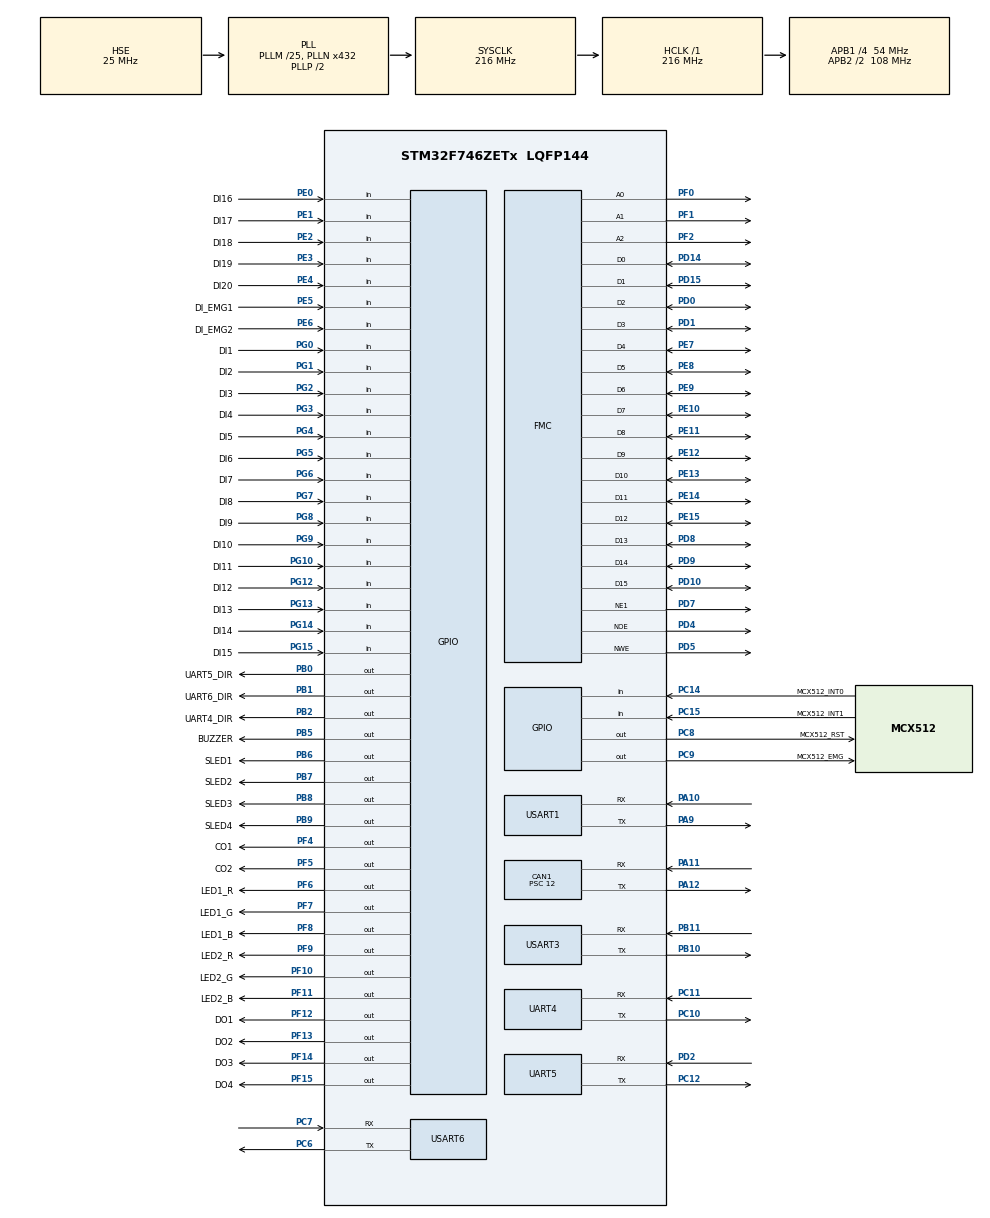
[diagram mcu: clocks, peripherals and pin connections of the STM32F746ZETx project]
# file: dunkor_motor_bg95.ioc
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CAN1.BS1=CAN_BS1_15TQ
CAN1.BS2=CAN_BS2_2TQ
CAN1.CalculateBaudRate=250000
CAN1.CalculateTimeBit=4000
CAN1.CalculateTimeQuantum=222.22222222222223
CAN1.Prescaler=12
CORTEX_M7.AccessPermission-Cortex_Memory_Protection_Unit_Region1_Settings=MPU_REGION_FULL_ACCESS
CORTEX_M7.AccessPermission-Cortex_Memory_Protection_Unit_Region2_Settings=MPU_REGION_FULL_ACCESS
CORTEX_M7.BaseAddress-Cortex_Memory_Protection_Unit_Region0_Settings=0x90000000
CORTEX_M7.CPU_DCache=Enabled
CORTEX_M7.CPU_ICache=Enabled
CORTEX_M7.DisableExec-Cortex_Memory_Protection_Unit_Region0_Settings=MPU_INSTRUCTION_ACCESS_DISABLE
CORTEX_M7.DisableExec-Cortex_Memory_Protection_Unit_Region1_Settings=MPU_INSTRUCTION_ACCESS_DISABLE
CORTEX_M7.Enable-Cortex_Memory_Protection_Unit_Region0_Settings=MPU_REGION_ENABLE
CORTEX_M7.Enable-Cortex_Memory_Protection_Unit_Region1_Settings=MPU_REGION_ENABLE
CORTEX_M7.Enable-Cortex_Memory_Protection_Unit_Region2_Settings=MPU_REGION_ENABLE
CORTEX_M7.IsBufferable-Cortex_Memory_Protection_Unit_Region1_Settings=MPU_ACCESS_BUFFERABLE
CORTEX_M7.IsBufferable-Cortex_Memory_Protection_Unit_Region2_Settings=MPU_ACCESS_BUFFERABLE
CORTEX_M7.IsCacheable-Cortex_Memory_Protection_Unit_Region1_Settings=MPU_ACCESS_CACHEABLE
CORTEX_M7.IsCacheable-Cortex_Memory_Protection_Unit_Region2_Settings=MPU_ACCESS_CACHEABLE
CORTEX_M7.MPU_Control=__NULL
CORTEX_M7.PREFETCH_ENABLE=0
CORTEX_M7.Size-Cortex_Memory_Protection_Unit_Region0_Settings=MPU_REGION_SIZE_512MB
CORTEX_M7.Size-Cortex_Memory_Protection_Unit_Region1_Settings=MPU_REGION_SIZE_16MB
CORTEX_M7.Size-Cortex_Memory_Protection_Unit_Region2_Settings=MPU_REGION_SIZE_1MB
FMC.AddressSetupTime1=5
FMC.BusTurnAroundDuration1=4
FMC.DataSetupTime1=4
FMC.WriteFifo1=FMC_WRITE_FIFO_DISABLE
FMC.WriteFifo2=FMC_WRITE_FIFO_DISABLE
FMC.WriteFifo3=FMC_WRITE_FIFO_DISABLE
FMC.WriteFifo4=FMC_WRITE_FIFO_DISABLE
Mcu.Family=STM32F7
Mcu.Name=STM32F746ZETx
Mcu.Package=LQFP144
NVIC.CAN1_RX0_IRQn=true\:8\:0\:true\:false\:true\:true\:true\:true
NVIC.PriorityGroup=NVIC_PRIORITYGROUP_4
NVIC.TIM6_DAC_IRQn=true\:15\:0\:false\:false\:true\:false\:true\:true
NVIC.TIM7_IRQn=true\:7\:0\:true\:false\:true\:true\:true\:true
NVIC.TimeBase=TIM6_DAC_IRQn
NVIC.TimeBaseIP=TIM6
NVIC.UART4_IRQn=true\:8\:0\:true\:false\:true\:true\:true\:true
NVIC.UART5_IRQn=true\:0\:0\:false\:false\:true\:true\:true\:true
NVIC.USART1_IRQn=true\:14\:0\:true\:false\:true\:true\:true\:true
NVIC.USART3_IRQn=true\:8\:0\:true\:false\:true\:true\:true\:true
NVIC.USART6_IRQn=true\:8\:0\:true\:false\:true\:true\:true\:true
PA10.Mode=Asynchronous
PA10.Signal=USART1_RX
PA11.Mode=CAN_Activate
PA11.Signal=CAN1_RX
PA12.Mode=CAN_Activate
PA12.Signal=CAN1_TX
PA13.Mode=JTAG_5_pins
PA13.Signal=SYS_JTMS-SWDIO
PA14.Mode=JTAG_5_pins
PA14.Signal=SYS_JTCK-SWCLK
PA15.Mode=JTAG_5_pins
PA15.Signal=SYS_JTDI
PA9.Mode=Asynchronous
PA9.Signal=USART1_TX
PB0.GPIO_Label=UART5_DIR
PB0.Signal=GPIO_Output
PB1.GPIO_Label=UART6_DIR
PB1.Signal=GPIO_Output
PB10.Mode=Asynchronous
PB10.Signal=USART3_TX
PB11.Mode=Asynchronous
PB11.Signal=USART3_RX
PB2.GPIO_Label=UART4_DIR
PB2.Signal=GPIO_Output
PB3.Mode=JTAG_5_pins
PB3.Signal=SYS_JTDO-SWO
PB4.Mode=JTAG_5_pins
PB4.Signal=SYS_JTRST
PB5.GPIO_Label=BUZZER
PB5.GPIO_Speed=GPIO_SPEED_FREQ_HIGH
PB5.Signal=GPIO_Output
PB6.GPIO_Label=SLED1
PB6.Signal=GPIO_Output
PB7.GPIO_Label=SLED2
PB7.Signal=GPIO_Output
PB8.GPIO_Label=SLED3
PB8.Signal=GPIO_Output
PB9.GPIO_Label=SLED4
PB9.Signal=GPIO_Output
PC10.Mode=Asynchronous
PC10.Signal=UART4_TX
PC11.Mode=Asynchronous
PC11.Signal=UART4_RX
PC12.Mode=Asynchronous
PC12.Signal=UART5_TX
PC14/OSC32_IN.GPIO_Label=MCX512_INT0
PC14/OSC32_IN.Signal=GPIO_Input
PC15/OSC32_OUT.GPIO_Label=MCX512_INT1
PC15/OSC32_OUT.Signal=GPIO_Input
PC6.Mode=Asynchronous
PC6.Signal=USART6_TX
PC7.Mode=Asynchronous
PC7.Signal=USART6_RX
PC8.GPIO_Label=MCX512_RST
PC8.Signal=GPIO_Output
PC9.GPIO_Label=MCX512_EMG
PC9.Signal=GPIO_Output
PD0.Signal=FMC_D2_DA2
PD1.Signal=FMC_D3_DA3
PD10.Signal=FMC_D15_DA15
PD14.Signal=FMC_D0_DA0
PD15.Signal=FMC_D1_DA1
PD2.Mode=Asynchronous
PD2.Signal=UART5_RX
PD4.Signal=FMC_NOE
PD5.Signal=FMC_NWE
PD7.Mode=NorPsramChipSelect1_1
PD7.Signal=FMC_NE1
PD8.Signal=FMC_D13_DA13
PD9.Signal=FMC_D14_DA14
PE0.GPIO_Label=DI16
PE0.Signal=GPIO_Input
PE1.GPIO_Label=DI17
PE1.Signal=GPIO_Input
PE10.Signal=FMC_D7_DA7
PE11.Signal=FMC_D8_DA8
PE12.Signal=FMC_D9_DA9
PE13.Signal=FMC_D10_DA10
PE14.Signal=FMC_D11_DA11
PE15.Signal=FMC_D12_DA12
PE2.GPIO_Label=DI18
PE2.Signal=GPIO_Input
PE3.GPIO_Label=DI19
PE3.Signal=GPIO_Input
PE4.GPIO_Label=DI20
PE4.Signal=GPIO_Input
PE5.GPIO_Label=DI_EMG1
PE5.Signal=GPIO_Input
PE6.GPIO_Label=DI_EMG2
PE6.Signal=GPIO_Input
PE7.Signal=FMC_D4_DA4
PE8.Signal=FMC_D5_DA5
PE9.Signal=FMC_D6_DA6
PF0.Signal=FMC_A0
PF1.Signal=FMC_A1
PF10.GPIO_Label=LED2_G
PF10.Signal=GPIO_Output
PF11.GPIO_Label=LED2_B
PF11.Signal=GPIO_Output
PF12.GPIO_Label=DO1
PF12.Signal=GPIO_Output
PF13.GPIO_Label=DO2
PF13.Signal=GPIO_Output
PF14.GPIO_Label=DO3
PF14.Signal=GPIO_Output
PF15.GPIO_Label=DO4
PF15.Signal=GPIO_Output
PF2.Signal=FMC_A2
PF4.GPIO_Label=CO1
PF4.Signal=GPIO_Output
PF5.GPIO_Label=CO2
PF5.Signal=GPIO_Output
PF6.GPIO_Label=LED1_R
PF6.Signal=GPIO_Output
PF7.GPIO_Label=LED1_G
PF7.Signal=GPIO_Output
PF8.GPIO_Label=LED1_B
PF8.Signal=GPIO_Output
PF9.GPIO_Label=LED2_R
PF9.Signal=GPIO_Output
PG0.GPIO_Label=DI1
PG0.Signal=GPIO_Input
PG1.GPIO_Label=DI2
PG1.Signal=GPIO_Input
PG10.GPIO_Label=DI11
PG10.Signal=GPIO_Input
PG12.GPIO_Label=DI12
PG12.Signal=GPIO_Input
PG13.GPIO_Label=DI13
PG13.Signal=GPIO_Input
PG14.GPIO_Label=DI14
PG14.Signal=GPIO_Input
PG15.GPIO_Label=DI15
PG15.Signal=GPIO_Input
PG2.GPIO_Label=DI3
PG2.Signal=GPIO_Input
PG3.GPIO_Label=DI4
PG3.Signal=GPIO_Input
PG4.GPIO_Label=DI5
PG4.Signal=GPIO_Input
PG5.GPIO_Label=DI6
PG5.Signal=GPIO_Input
PG6.GPIO_Label=DI7
PG6.Signal=GPIO_Input
PG7.GPIO_Label=DI8
PG7.Signal=GPIO_Input
PG8.GPIO_Label=DI9
PG8.Signal=GPIO_Input
PG9.GPIO_Label=DI10
PG9.Signal=GPIO_Input
PH0/OSC_IN.Mode=HSE-External-Oscillator
PH0/OSC_IN.Signal=RCC_OSC_IN
PH1/OSC_OUT.Mode=HSE-External-Oscillator
PH1/OSC_OUT.Signal=RCC_OSC_OUT
ProjectManager.HeapSize=0x2000
ProjectManager.StackSize=0x4000
ProjectManager.TargetToolchain=STM32CubeIDE
RCC.AHBFreq_Value=216000000
RCC.APB1CLKDivider=RCC_HCLK_DIV4
RCC.APB1Freq_Value=54000000
RCC.APB1TimFreq_Value=108000000
RCC.APB2CLKDivider=RCC_HCLK_DIV2
RCC.APB2Freq_Value=108000000
RCC.APB2TimFreq_Value=216000000
RCC.CortexFreq_Value=216000000
RCC.HCLKFreq_Value=216000000
RCC.HSE_VALUE=25000000
RCC.HSI_VALUE=16000000
RCC.LSE_VALUE=32768
RCC.PLLM=25
RCC.PLLN=432
RCC.PLLSourceVirtual=RCC_PLLSOURCE_HSE
RCC.SYSCLKFreq_VALUE=216000000
RCC.SYSCLKSource=RCC_SYSCLKSOURCE_PLLCLK
RCC.USBFreq_Value=216000000
RCC.VCOOutputFreq_Value=432000000
SH.FMC_A0.0=FMC_A0,3b-a1
SH.FMC_A1.0=FMC_A1,3b-a1
SH.FMC_A2.0=FMC_A2,3b-a1
SH.FMC_D0_DA0.0=FMC_D0,16b-d1
SH.FMC_D10_DA10.0=FMC_D10,16b-d1
SH.FMC_D11_DA11.0=FMC_D11,16b-d1
SH.FMC_D12_DA12.0=FMC_D12,16b-d1
SH.FMC_D13_DA13.0=FMC_D13,16b-d1
SH.FMC_D14_DA14.0=FMC_D14,16b-d1
SH.FMC_D15_DA15.0=FMC_D15,16b-d1
SH.FMC_D1_DA1.0=FMC_D1,16b-d1
SH.FMC_D2_DA2.0=FMC_D2,16b-d1
SH.FMC_D3_DA3.0=FMC_D3,16b-d1
SH.FMC_D4_DA4.0=FMC_D4,16b-d1
SH.FMC_D5_DA5.0=FMC_D5,16b-d1
SH.FMC_D6_DA6.0=FMC_D6,16b-d1
SH.FMC_D7_DA7.0=FMC_D7,16b-d1
SH.FMC_D8_DA8.0=FMC_D8,16b-d1
SH.FMC_D9_DA9.0=FMC_D9,16b-d1
SH.FMC_NOE.0=FMC_NOE,Psram1
SH.FMC_NWE.0=FMC_NWE,Psram1
TIM7.AutoReloadPreload=TIM_AUTORELOAD_PRELOAD_ENABLE
TIM7.Period=99
TIM7.Prescaler=107
UART5.Parity=PARITY_EVEN
UART5.WordLength=WORDLENGTH_9B
USART1.VirtualMode-Asynchronous=VM_ASYNC
USART3.VirtualMode-Asynchronous=VM_ASYNC
USART6.Parity=PARITY_EVEN
USART6.VirtualMode-Asynchronous=VM_ASYNC
USART6.WordLength=WORDLENGTH_9B
VP_SYS_VS_tim6.Mode=TIM6
VP_TIM7_VS_ClockSourceINT.Mode=Enable_Timer
board=custom

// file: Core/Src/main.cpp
/* USER CODE BEGIN Header */
/**
  ******************************************************************************
  * @file           : main.c
  * @brief          : Main program body
  ******************************************************************************
  * @attention
  *
  * Copyright (c) 2023 STMicroelectronics.
  * All rights reserved.
  *
  * This software is licensed under terms that can be found in the LICENSE file
  * in the root directory of this software component.
  * If no LICENSE file comes with this software, it is provided AS-IS.
  *
  ******************************************************************************
  */
/* USER CODE END Header */
#include "main.h"

/* USER CODE BEGIN Includes */
#include "lift_motor/bg95.h"
/* USER CODE END Includes */

CAN_HandleTypeDef hcan1;

TIM_HandleTypeDef htim7;

UART_HandleTypeDef huart4;
UART_HandleTypeDef huart5;
UART_HandleTypeDef huart1;
UART_HandleTypeDef huart3;
UART_HandleTypeDef huart6;

SRAM_HandleTypeDef hsram1;

void SystemClock_Config(void);
static void MX_GPIO_Init(void);
static void MX_CAN1_Init(void);
static void MX_FMC_Init(void);
static void MX_UART4_Init(void);
static void MX_USART1_UART_Init(void);
static void MX_USART3_UART_Init(void);
static void MX_USART6_UART_Init(void);
static void MX_UART5_Init(void);
static void MX_TIM7_Init(void);

int main(void)
{

  /* Enable I-Cache---------------------------------------------------------*/
  SCB_EnableICache();

  /* Enable D-Cache---------------------------------------------------------*/
  SCB_EnableDCache();

  /* MCU Configuration--------------------------------------------------------*/

  /* Reset of all peripherals, Initializes the Flash interface and the Systick. */
  HAL_Init();

  /* Configure the system clock */
  SystemClock_Config();

  /* Initialize all configured peripherals */
  MX_GPIO_Init();
  MX_CAN1_Init();
  MX_FMC_Init();
  MX_UART4_Init();
  MX_USART1_UART_Init();
  MX_USART3_UART_Init();
  MX_USART6_UART_Init();
  MX_UART5_Init();
  MX_TIM7_Init();

  /* USER CODE BEGIN 2 */
  /*Constructor*/
  BG95 lift_motor(&hcan1, 127);

  lift_motor.Initialization();
  /* USER CODE END 2 */

  /* Infinite loop */
  while (1)
  {
	  //lift_motor.VelCommand(300, 100, 100);

	  lift_motor.Drive();

	  HAL_Delay(1);

	  //int32_t your_pos_val = lift_motor.GetMotorPosition();

  }
}

void SystemClock_Config(void)
{
  RCC_OscInitTypeDef RCC_OscInitStruct = {0};
  RCC_ClkInitTypeDef RCC_ClkInitStruct = {0};

  /** Configure the main internal regulator output voltage
  */
  __HAL_RCC_PWR_CLK_ENABLE();
  __HAL_PWR_VOLTAGESCALING_CONFIG(PWR_REGULATOR_VOLTAGE_SCALE1);

  /** Initializes the RCC Oscillators according to the specified parameters
  * in the RCC_OscInitTypeDef structure.
  */
  RCC_OscInitStruct.OscillatorType = RCC_OSCILLATORTYPE_HSE;
  RCC_OscInitStruct.HSEState = RCC_HSE_ON;
  RCC_OscInitStruct.PLL.PLLState = RCC_PLL_ON;
  RCC_OscInitStruct.PLL.PLLSource = RCC_PLLSOURCE_HSE;
  RCC_OscInitStruct.PLL.PLLM = 25;
  RCC_OscInitStruct.PLL.PLLN = 432;
  RCC_OscInitStruct.PLL.PLLP = RCC_PLLP_DIV2;
  RCC_OscInitStruct.PLL.PLLQ = 2;
  if (HAL_RCC_OscConfig(&RCC_OscInitStruct) != HAL_OK)
  {
    Error_Handler();
  }

  /** Activate the Over-Drive mode
  */
  if (HAL_PWREx_EnableOverDrive() != HAL_OK)
  {
    Error_Handler();
  }

  /** Initializes the CPU, AHB and APB buses clocks
  */
  RCC_ClkInitStruct.ClockType = RCC_CLOCKTYPE_HCLK|RCC_CLOCKTYPE_SYSCLK
                              |RCC_CLOCKTYPE_PCLK1|RCC_CLOCKTYPE_PCLK2;
  RCC_ClkInitStruct.SYSCLKSource = RCC_SYSCLKSOURCE_PLLCLK;
  RCC_ClkInitStruct.AHBCLKDivider = RCC_SYSCLK_DIV1;
  RCC_ClkInitStruct.APB1CLKDivider = RCC_HCLK_DIV4;
  RCC_ClkInitStruct.APB2CLKDivider = RCC_HCLK_DIV2;

  if (HAL_RCC_ClockConfig(&RCC_ClkInitStruct, FLASH_LATENCY_7) != HAL_OK)
  {
    Error_Handler();
  }
}

static void MX_CAN1_Init(void)
{

  hcan1.Instance = CAN1;
  hcan1.Init.Prescaler = 12;
  hcan1.Init.Mode = CAN_MODE_NORMAL;
  hcan1.Init.SyncJumpWidth = CAN_SJW_1TQ;
  hcan1.Init.TimeSeg1 = CAN_BS1_15TQ;
  hcan1.Init.TimeSeg2 = CAN_BS2_2TQ;
  hcan1.Init.TimeTriggeredMode = DISABLE;
  hcan1.Init.AutoBusOff = DISABLE;
  hcan1.Init.AutoWakeUp = DISABLE;
  hcan1.Init.AutoRetransmission = DISABLE;
  hcan1.Init.ReceiveFifoLocked = DISABLE;
  hcan1.Init.TransmitFifoPriority = DISABLE;
  if (HAL_CAN_Init(&hcan1) != HAL_OK)
  {
    Error_Handler();
  }

}

static void MX_TIM7_Init(void)
{

  TIM_MasterConfigTypeDef sMasterConfig = {0};

  htim7.Instance = TIM7;
  htim7.Init.Prescaler = 107;
  htim7.Init.CounterMode = TIM_COUNTERMODE_UP;
  htim7.Init.Period = 99;
  htim7.Init.AutoReloadPreload = TIM_AUTORELOAD_PRELOAD_ENABLE;
  if (HAL_TIM_Base_Init(&htim7) != HAL_OK)
  {
    Error_Handler();
  }
  sMasterConfig.MasterOutputTrigger = TIM_TRGO_RESET;
  sMasterConfig.MasterSlaveMode = TIM_MASTERSLAVEMODE_DISABLE;
  if (HAL_TIMEx_MasterConfigSynchronization(&htim7, &sMasterConfig) != HAL_OK)
  {
    Error_Handler();
  }

}

static void MX_UART4_Init(void)
{

  huart4.Instance = UART4;
  huart4.Init.BaudRate = 115200;
  huart4.Init.WordLength = UART_WORDLENGTH_8B;
  huart4.Init.StopBits = UART_STOPBITS_1;
  huart4.Init.Parity = UART_PARITY_NONE;
  huart4.Init.Mode = UART_MODE_TX_RX;
  huart4.Init.HwFlowCtl = UART_HWCONTROL_NONE;
  huart4.Init.OverSampling = UART_OVERSAMPLING_16;
  huart4.Init.OneBitSampling = UART_ONE_BIT_SAMPLE_DISABLE;
  huart4.AdvancedInit.AdvFeatureInit = UART_ADVFEATURE_NO_INIT;
  if (HAL_UART_Init(&huart4) != HAL_OK)
  {
    Error_Handler();
  }

}

static void MX_UART5_Init(void)
{

  huart5.Instance = UART5;
  huart5.Init.BaudRate = 115200;
  huart5.Init.WordLength = UART_WORDLENGTH_9B;
  huart5.Init.StopBits = UART_STOPBITS_1;
  huart5.Init.Parity = UART_PARITY_EVEN;
  huart5.Init.Mode = UART_MODE_TX_RX;
  huart5.Init.HwFlowCtl = UART_HWCONTROL_NONE;
  huart5.Init.OverSampling = UART_OVERSAMPLING_16;
  huart5.Init.OneBitSampling = UART_ONE_BIT_SAMPLE_DISABLE;
  huart5.AdvancedInit.AdvFeatureInit = UART_ADVFEATURE_NO_INIT;
  if (HAL_UART_Init(&huart5) != HAL_OK)
  {
    Error_Handler();
  }

}

static void MX_USART1_UART_Init(void)
{

  huart1.Instance = USART1;
  huart1.Init.BaudRate = 115200;
  huart1.Init.WordLength = UART_WORDLENGTH_8B;
  huart1.Init.StopBits = UART_STOPBITS_1;
  huart1.Init.Parity = UART_PARITY_NONE;
  huart1.Init.Mode = UART_MODE_TX_RX;
  huart1.Init.HwFlowCtl = UART_HWCONTROL_NONE;
  huart1.Init.OverSampling = UART_OVERSAMPLING_16;
  huart1.Init.OneBitSampling = UART_ONE_BIT_SAMPLE_DISABLE;
  huart1.AdvancedInit.AdvFeatureInit = UART_ADVFEATURE_NO_INIT;
  if (HAL_UART_Init(&huart1) != HAL_OK)
  {
    Error_Handler();
  }

}

static void MX_USART3_UART_Init(void)
{

  huart3.Instance = USART3;
  huart3.Init.BaudRate = 115200;
  huart3.Init.WordLength = UART_WORDLENGTH_8B;
  huart3.Init.StopBits = UART_STOPBITS_1;
  huart3.Init.Parity = UART_PARITY_NONE;
  huart3.Init.Mode = UART_MODE_TX_RX;
  huart3.Init.HwFlowCtl = UART_HWCONTROL_NONE;
  huart3.Init.OverSampling = UART_OVERSAMPLING_16;
  huart3.Init.OneBitSampling = UART_ONE_BIT_SAMPLE_DISABLE;
  huart3.AdvancedInit.AdvFeatureInit = UART_ADVFEATURE_NO_INIT;
  if (HAL_UART_Init(&huart3) != HAL_OK)
  {
    Error_Handler();
  }

}

static void MX_USART6_UART_Init(void)
{

  huart6.Instance = USART6;
  huart6.Init.BaudRate = 115200;
  huart6.Init.WordLength = UART_WORDLENGTH_9B;
  huart6.Init.StopBits = UART_STOPBITS_1;
  huart6.Init.Parity = UART_PARITY_EVEN;
  huart6.Init.Mode = UART_MODE_TX_RX;
  huart6.Init.HwFlowCtl = UART_HWCONTROL_NONE;
  huart6.Init.OverSampling = UART_OVERSAMPLING_16;
  huart6.Init.OneBitSampling = UART_ONE_BIT_SAMPLE_DISABLE;
  huart6.AdvancedInit.AdvFeatureInit = UART_ADVFEATURE_NO_INIT;
  if (HAL_UART_Init(&huart6) != HAL_OK)
  {
    Error_Handler();
  }

}

/* FMC initialization function */
static void MX_FMC_Init(void)
{

  FMC_NORSRAM_TimingTypeDef Timing = {0};

  /** Perform the SRAM1 memory initialization sequence
  */
  hsram1.Instance = FMC_NORSRAM_DEVICE;
  hsram1.Extended = FMC_NORSRAM_EXTENDED_DEVICE;
  /* hsram1.Init */
  hsram1.Init.NSBank = FMC_NORSRAM_BANK1;
  hsram1.Init.DataAddressMux = FMC_DATA_ADDRESS_MUX_DISABLE;
  hsram1.Init.MemoryType = FMC_MEMORY_TYPE_PSRAM;
  hsram1.Init.MemoryDataWidth = FMC_NORSRAM_MEM_BUS_WIDTH_16;
  hsram1.Init.BurstAccessMode = FMC_BURST_ACCESS_MODE_DISABLE;
  hsram1.Init.WaitSignalPolarity = FMC_WAIT_SIGNAL_POLARITY_LOW;
  hsram1.Init.WaitSignalActive = FMC_WAIT_TIMING_BEFORE_WS;
  hsram1.Init.WriteOperation = FMC_WRITE_OPERATION_DISABLE;
  hsram1.Init.WaitSignal = FMC_WAIT_SIGNAL_DISABLE;
  hsram1.Init.ExtendedMode = FMC_EXTENDED_MODE_DISABLE;
  hsram1.Init.AsynchronousWait = FMC_ASYNCHRONOUS_WAIT_DISABLE;
  hsram1.Init.WriteBurst = FMC_WRITE_BURST_DISABLE;
  hsram1.Init.ContinuousClock = FMC_CONTINUOUS_CLOCK_SYNC_ONLY;
  hsram1.Init.WriteFifo = FMC_WRITE_FIFO_DISABLE;
  hsram1.Init.PageSize = FMC_PAGE_SIZE_NONE;
  /* Timing */
  Timing.AddressSetupTime = 5;
  Timing.AddressHoldTime = 15;
  Timing.DataSetupTime = 4;
  Timing.BusTurnAroundDuration = 4;
  Timing.CLKDivision = 16;
  Timing.DataLatency = 17;
  Timing.AccessMode = FMC_ACCESS_MODE_A;
  /* ExtTiming */

  if (HAL_SRAM_Init(&hsram1, &Timing, NULL) != HAL_OK)
  {
    Error_Handler( );
  }

}

static void MX_GPIO_Init(void)
{
  GPIO_InitTypeDef GPIO_InitStruct = {0};

  /* GPIO Ports Clock Enable */
  __HAL_RCC_GPIOE_CLK_ENABLE();
  __HAL_RCC_GPIOC_CLK_ENABLE();
  __HAL_RCC_GPIOF_CLK_ENABLE();
  __HAL_RCC_GPIOH_CLK_ENABLE();
  __HAL_RCC_GPIOB_CLK_ENABLE();
  __HAL_RCC_GPIOG_CLK_ENABLE();
  __HAL_RCC_GPIOD_CLK_ENABLE();
  __HAL_RCC_GPIOA_CLK_ENABLE();

  /*Configure GPIO pin Output Level */
  HAL_GPIO_WritePin(GPIOF, CO1_Pin|CO2_Pin|LED1_R_Pin|LED1_G_Pin
                          |LED1_B_Pin|LED2_R_Pin|LED2_G_Pin|LED2_B_Pin
                          |DO1_Pin|DO2_Pin|DO3_Pin|DO4_Pin, GPIO_PIN_RESET);

  /*Configure GPIO pin Output Level */
  HAL_GPIO_WritePin(GPIOB, UART5_DIR_Pin|UART6_DIR_Pin|UART4_DIR_Pin|BUZZER_Pin
                          |SLED1_Pin|SLED2_Pin|SLED3_Pin|SLED4_Pin, GPIO_PIN_RESET);

  /*Configure GPIO pin Output Level */
  HAL_GPIO_WritePin(GPIOC, MCX512_RST_Pin|MCX512_EMG_Pin, GPIO_PIN_RESET);

  /*Configure GPIO pins : DI18_Pin DI19_Pin DI20_Pin DI_EMG1_Pin
                           DI_EMG2_Pin DI16_Pin DI17_Pin */
  GPIO_InitStruct.Pin = DI18_Pin|DI19_Pin|DI20_Pin|DI_EMG1_Pin
                          |DI_EMG2_Pin|DI16_Pin|DI17_Pin;
  GPIO_InitStruct.Mode = GPIO_MODE_INPUT;
  GPIO_InitStruct.Pull = GPIO_NOPULL;
  HAL_GPIO_Init(GPIOE, &GPIO_InitStruct);

  /*Configure GPIO pins : MCX512_INT0_Pin MCX512_INT1_Pin */
  GPIO_InitStruct.Pin = MCX512_INT0_Pin|MCX512_INT1_Pin;
  GPIO_InitStruct.Mode = GPIO_MODE_INPUT;
  GPIO_InitStruct.Pull = GPIO_NOPULL;
  HAL_GPIO_Init(GPIOC, &GPIO_InitStruct);

  /*Configure GPIO pins : CO1_Pin CO2_Pin LED1_R_Pin LED1_G_Pin
                           LED1_B_Pin LED2_R_Pin LED2_G_Pin LED2_B_Pin
                           DO1_Pin DO2_Pin DO3_Pin DO4_Pin */
  GPIO_InitStruct.Pin = CO1_Pin|CO2_Pin|LED1_R_Pin|LED1_G_Pin
                          |LED1_B_Pin|LED2_R_Pin|LED2_G_Pin|LED2_B_Pin
                          |DO1_Pin|DO2_Pin|DO3_Pin|DO4_Pin;
  GPIO_InitStruct.Mode = GPIO_MODE_OUTPUT_PP;
  GPIO_InitStruct.Pull = GPIO_NOPULL;
  GPIO_InitStruct.Speed = GPIO_SPEED_FREQ_LOW;
  HAL_GPIO_Init(GPIOF, &GPIO_InitStruct);

  /*Configure GPIO pins : UART5_DIR_Pin UART6_DIR_Pin UART4_DIR_Pin SLED1_Pin
                           SLED2_Pin SLED3_Pin SLED4_Pin */
  GPIO_InitStruct.Pin = UART5_DIR_Pin|UART6_DIR_Pin|UART4_DIR_Pin|SLED1_Pin
                          |SLED2_Pin|SLED3_Pin|SLED4_Pin;
  GPIO_InitStruct.Mode = GPIO_MODE_OUTPUT_PP;
  GPIO_InitStruct.Pull = GPIO_NOPULL;
  GPIO_InitStruct.Speed = GPIO_SPEED_FREQ_LOW;
  HAL_GPIO_Init(GPIOB, &GPIO_InitStruct);

  /*Configure GPIO pins : DI1_Pin DI2_Pin DI3_Pin DI4_Pin
                           DI5_Pin DI6_Pin DI7_Pin DI8_Pin
                           DI9_Pin DI10_Pin DI11_Pin DI12_Pin
                           DI13_Pin DI14_Pin DI15_Pin */
  GPIO_InitStruct.Pin = DI1_Pin|DI2_Pin|DI3_Pin|DI4_Pin
                          |DI5_Pin|DI6_Pin|DI7_Pin|DI8_Pin
                          |DI9_Pin|DI10_Pin|DI11_Pin|DI12_Pin
                          |DI13_Pin|DI14_Pin|DI15_Pin;
  GPIO_InitStruct.Mode = GPIO_MODE_INPUT;
  GPIO_InitStruct.Pull = GPIO_NOPULL;
  HAL_GPIO_Init(GPIOG, &GPIO_InitStruct);

  /*Configure GPIO pins : MCX512_RST_Pin MCX512_EMG_Pin */
  GPIO_InitStruct.Pin = MCX512_RST_Pin|MCX512_EMG_Pin;
  GPIO_InitStruct.Mode = GPIO_MODE_OUTPUT_PP;
  GPIO_InitStruct.Pull = GPIO_NOPULL;
  GPIO_InitStruct.Speed = GPIO_SPEED_FREQ_LOW;
  HAL_GPIO_Init(GPIOC, &GPIO_InitStruct);

  /*Configure GPIO pin : BUZZER_Pin */
  GPIO_InitStruct.Pin = BUZZER_Pin;
  GPIO_InitStruct.Mode = GPIO_MODE_OUTPUT_PP;
  GPIO_InitStruct.Pull = GPIO_NOPULL;
  GPIO_InitStruct.Speed = GPIO_SPEED_FREQ_HIGH;
  HAL_GPIO_Init(BUZZER_GPIO_Port, &GPIO_InitStruct);

}

void HAL_TIM_PeriodElapsedCallback(TIM_HandleTypeDef *htim)
{
  if (htim->Instance == TIM6) {
    HAL_IncTick();
  }
}

void Error_Handler(void)
{
  __disable_irq();
  while (1)
  {
  }
}
